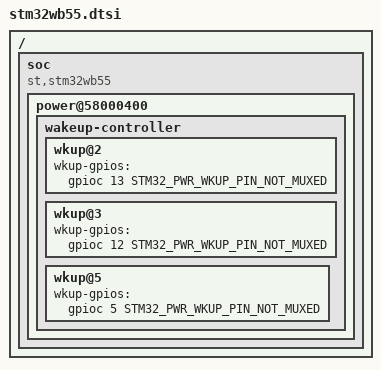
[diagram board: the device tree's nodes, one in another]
/*
 * Copyright (c) 2018 Linaro Limited
 *
 * SPDX-License-Identifier: Apache-2.0
 */

#include <st/wb/stm32wb.dtsi>

/ {
	soc {
		compatible = "st,stm32wb55", "st,stm32wb", "simple-bus";

		power@58000400 {
			wakeup-controller {
				wkup@2 {
					wkup-gpios = <&gpioc 13 STM32_PWR_WKUP_PIN_NOT_MUXED>;
				};

				wkup@3 {
					wkup-gpios = <&gpioc 12 STM32_PWR_WKUP_PIN_NOT_MUXED>;
				};

				wkup@5 {
					wkup-gpios = <&gpioc 5 STM32_PWR_WKUP_PIN_NOT_MUXED>;
				};
			};
		};
	};
};
